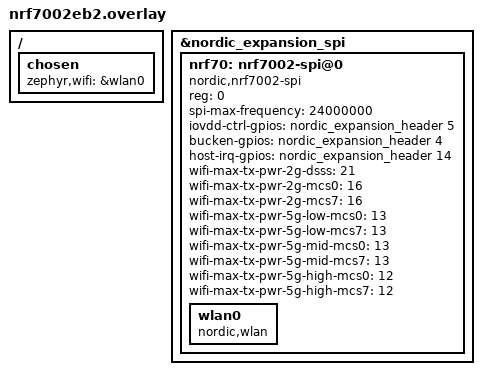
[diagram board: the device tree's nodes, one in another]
/*
* Copyright (c) 2026 Paulus Schulinck (Github @PaulskPt)
*
* SPDX-License-Identifier: MIT
* Note @PaulskPt: info from Microsoft Copilot assistant:
* 
*/

/ {
    chosen {
        zephyr,wifi = &wlan0;
    };
};

&nordic_expansion_spi {
    status = "okay";

    nrf70: nrf7002-spi@0 {
        compatible = "nordic,nrf7002-spi";
        status = "okay";

        /* Common assignments for nRF70 EB-II shield */
        reg = <0>;
        spi-max-frequency = <24000000>;

        /* Mandatory IRQ and IO pins from expansion header */
        iovdd-ctrl-gpios = <&nordic_expansion_header 5 GPIO_ACTIVE_HIGH>;
        bucken-gpios     = <&nordic_expansion_header 4 GPIO_ACTIVE_HIGH>;
        host-irq-gpios   = <&nordic_expansion_header 14 GPIO_ACTIVE_HIGH>;

        /* Maximum TX power limits */
        wifi-max-tx-pwr-2g-dsss = <21>;
        wifi-max-tx-pwr-2g-mcs0 = <16>;
        wifi-max-tx-pwr-2g-mcs7 = <16>;
        wifi-max-tx-pwr-5g-low-mcs0 = <13>;
        wifi-max-tx-pwr-5g-low-mcs7 = <13>;
        wifi-max-tx-pwr-5g-mid-mcs0 = <13>;
        wifi-max-tx-pwr-5g-mid-mcs7 = <13>;
        wifi-max-tx-pwr-5g-high-mcs0 = <12>;
        wifi-max-tx-pwr-5g-high-mcs7 = <12>;

        /* Wi-Fi interface */
        wlan0: wlan0 {
            compatible = "nordic,wlan";
        };
    };
};
